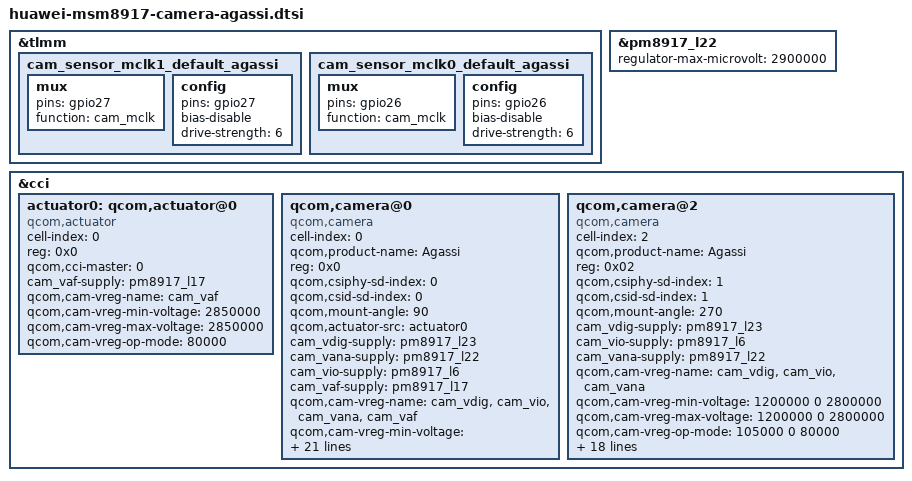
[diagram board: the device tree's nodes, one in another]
/*
 * Copyright (c) 2016, The Linux Foundation. All rights reserved.
 *
 * This program is free software; you can redistribute it and/or modify
 * it under the terms of the GNU General Public License version 2 and
 * only version 2 as published by the Free Software Foundation.
 *
 * This program is distributed in the hope that it will be useful,
 * but WITHOUT ANY WARRANTY; without even the implied warranty of
 * MERCHANTABILITY or FITNESS FOR A PARTICULAR PURPOSE.  See the
 * GNU General Public License for more details.
 */
&tlmm {

	cam_sensor_mclk1_default_agassi: cam_sensor_mclk1_default_agassi {
		/* MCLK1 */
		mux {
			/* CLK, DATA */
			pins = "gpio27";
			function = "cam_mclk";
		};
		config {
			pins = "gpio27";
			bias-disable; /* No PULL */
			drive-strength = <6>; /* 6 MA */
		};
	};

	cam_sensor_mclk0_default_agassi: cam_sensor_mclk0_default_agassi {
		/* MCLK0 */
		mux {
			/* CLK, DATA */
			pins = "gpio26";
			function = "cam_mclk";
		};
		config {
			pins = "gpio26";
			bias-disable; /* No PULL */
			drive-strength = <6>; /* 6 MA */
		};
	};
};

&pm8917_l22{
	        regulator-max-microvolt = <2900000>;
};


&cci {
	actuator0: qcom,actuator@0 {
		cell-index = <0>;
		reg = <0x0>;
		compatible = "qcom,actuator";
		qcom,cci-master = <0>;
		cam_vaf-supply = <&pm8917_l17>;
		qcom,cam-vreg-name = "cam_vaf";
		qcom,cam-vreg-min-voltage = <2850000>;
		qcom,cam-vreg-max-voltage = <2850000>;
		qcom,cam-vreg-op-mode = <80000>;
	};


	qcom,camera@0 {
		cell-index = <0>;
		compatible = "qcom,camera";
		qcom,product-name = "Agassi";
		reg = <0x0>;
		qcom,csiphy-sd-index = <0>;
		qcom,csid-sd-index = <0>;
		qcom,mount-angle = <90>;
		qcom,actuator-src = <&actuator0>;
		cam_vdig-supply = <&pm8917_l23>;
		cam_vana-supply = <&pm8917_l22>;
		cam_vio-supply = <&pm8917_l6>;
		cam_vaf-supply = <&pm8917_l17>;
		qcom,cam-vreg-name = "cam_vdig", "cam_vio", "cam_vana",
							"cam_vaf";
		qcom,cam-vreg-min-voltage = <1200000 0 2900000 2850000>;
		qcom,cam-vreg-max-voltage = <1200000 0 2900000 2850000>;
		qcom,cam-vreg-op-mode = <200000 0 80000 100000>;
		pinctrl-names = "cam_default", "cam_suspend";
		pinctrl-0 = <&cam_sensor_mclk0_default_agassi
				&cam_sensor_rear_default>;
		pinctrl-1 = <&cam_sensor_mclk0_sleep
				&cam_sensor_rear_sleep>;
		gpios = <&tlmm 26 0>,
			<&tlmm 36 0>,
			<&tlmm 35 0>;
		qcom,gpio-reset = <1>;
		qcom,gpio-standby = <2>;

		qcom,gpio-req-tbl-num = <0 1 2 >;
		qcom,gpio-req-tbl-flags = <1 0 0 >;
		qcom,gpio-req-tbl-label = "CAMIF_MCLK0",
			"CAM_RESET0",
			"CAM_STANDBY0";
		qcom,sensor-position = <0>;
		qcom,sensor-mode = <0>;
		qcom,cci-master = <0>;
		clocks = <&clock_gcc clk_mclk0_clk_src>,
			<&clock_gcc clk_gcc_camss_mclk0_clk>;
		clock-names = "cam_src_clk", "cam_clk";
		qcom,clock-rates = <24000000 0>;
	};

	qcom,camera@2 {
		cell-index = <2>;
		compatible = "qcom,camera";
		qcom,product-name = "Agassi";
		reg = <0x02>;
		qcom,csiphy-sd-index = <1>;
		qcom,csid-sd-index = <1>;
		qcom,mount-angle = <270>;
		cam_vdig-supply = <&pm8917_l23>;
		cam_vio-supply = <&pm8917_l6>;
                cam_vana-supply = <&pm8917_l22>;
		qcom,cam-vreg-name = "cam_vdig", "cam_vio", "cam_vana";
		qcom,cam-vreg-min-voltage = <1200000 0 2800000>;
		qcom,cam-vreg-max-voltage = <1200000 0 2800000>;
		qcom,cam-vreg-op-mode = <105000 0 80000>;
		qcom,gpio-no-mux = <0>;
		pinctrl-names = "cam_default", "cam_suspend";
		pinctrl-0 = <&cam_sensor_mclk1_default_agassi
				&cam_sensor_front1_default>;
		pinctrl-1 = <&cam_sensor_mclk1_sleep
				&cam_sensor_front1_sleep>;
		gpios = <&tlmm 27 0>,
			<&tlmm 40 0>,
			<&tlmm 39 0>;
		qcom,gpio-reset = <1>;
		qcom,gpio-standby = <2>;
		qcom,gpio-req-tbl-num = <0 1 2>;
		qcom,gpio-req-tbl-flags = <1 0 0>;
		qcom,gpio-req-tbl-label = "CAMIF_MCLK1",
					  "CAM_RESET1",
					  "CAM_STANDBY";
		qcom,sensor-position = <1>;
		qcom,sensor-mode = <0>;
		qcom,cci-master = <1>;
		clocks = <&clock_gcc clk_mclk1_clk_src>,
			<&clock_gcc clk_gcc_camss_mclk1_clk>;
		clock-names = "cam_src_clk", "cam_clk";
		qcom,clock-rates = <24000000 0>;
	};
};
